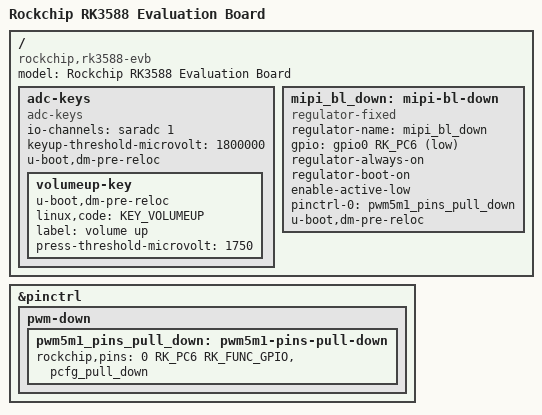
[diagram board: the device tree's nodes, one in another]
// SPDX-License-Identifier: (GPL-2.0+ OR MIT)
/*
 * Copyright (c) 2021 Rockchip Electronics Co., Ltd
 *
 */

/dts-v1/;
#include "rk3588.dtsi"
#include "rk3588-u-boot.dtsi"
#include <dt-bindings/input/input.h>

/ {
	model = "Rockchip RK3588 Evaluation Board";
	compatible = "rockchip,rk3588-evb", "rockchip,rk3588";

	adc-keys {
		compatible = "adc-keys";
		io-channels = <&saradc 1>;
		io-channel-names = "buttons";
		keyup-threshold-microvolt = <1800000>;
		u-boot,dm-pre-reloc;
		status = "okay";

		volumeup-key {
			u-boot,dm-pre-reloc;
			linux,code = <KEY_VOLUMEUP>;
			label = "volume up";
			press-threshold-microvolt = <1750>;
		};
	};

	mipi_bl_down: mipi-bl-down {
		compatible = "regulator-fixed";
		regulator-name = "mipi_bl_down";
		gpio = <&gpio0 RK_PC6 GPIO_ACTIVE_LOW>;
		regulator-always-on;
		regulator-boot-on;
		enable-active-low;
		pinctrl-names = "default";
		pinctrl-0 = <&pwm5m1_pins_pull_down>;
		u-boot,dm-pre-reloc;
	};
};

&pinctrl {
	pwm-down{
		pwm5m1_pins_pull_down: pwm5m1-pins-pull-down {
			rockchip,pins =
				/* pwm5_m1 */
				<0 RK_PC6 RK_FUNC_GPIO &pcfg_pull_down>;
		};
	};
};
